# V3s register map
Vendor: Allwinner; Series: V3s; File version: 0.1
CPU: ARM Cortex-A7 MP1 0, little endian, MPU, no FPU, 0 interrupt priority bits
Registers are 32-bit, read-write, reset 0x0 unless marked. A register's access mark holds for its fields unless they carry their own. Offsets are from the block's base; [hi:lo] are bit positions.

## USB_OTG_EHCI0/OHCI0 (part 2 of 2)
Base 0x01C1A000
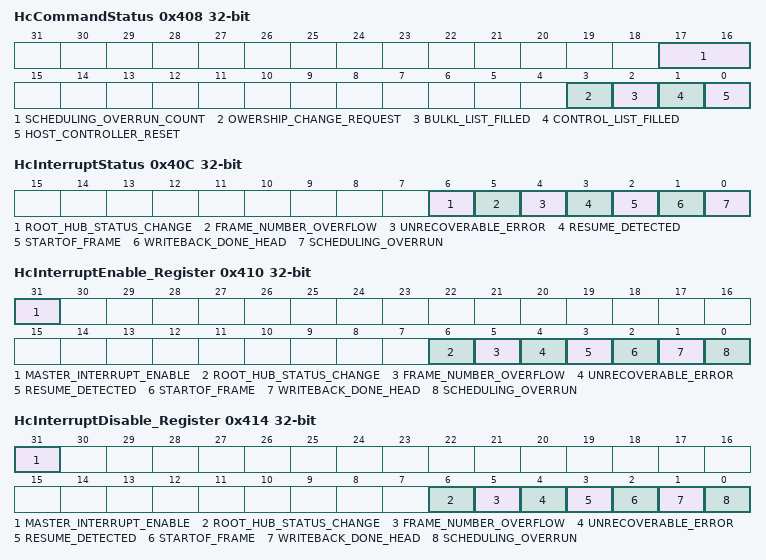
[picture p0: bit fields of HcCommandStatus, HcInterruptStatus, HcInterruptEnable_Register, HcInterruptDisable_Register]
0x408 HcCommandStatus
  [17:16] SCHEDULING_OVERRUN_COUNT ro — SchedulingOverrunCount These bits are incremented on each scheduling overrun error. It is initialized to 00b and wraps around at 11b. This will be incremented when a scheduling overrun is detected even if SchedulingOverrun in HcInterruptStatus has already been set. This is used by HCD to monitor any persistent scheduling problem.
  [3] OWERSHIP_CHANGE_REQUEST — OwershipChangeRequest This bit is set by an OS HCD to request a change of control of the HC. When set HC will set the OwnershipChange field in HcInterruptStatus. After the changeover, this bit is cleared and remains so until the next request from OS HCD.
  [2] BULKL_LIST_FILLED — BulklListFilled This bit is used to indicate whether there are any TDs on the Bulk list. It is set by HCD whenever it adds a TD to an ED in the Bulk list. When HC begins to process the head of the Bulk list, it checks BLF. As long as BulkListFilled is 0, HC will not start processing the Bulk list. If BulkListFilled is 1, HC will start processing the Bulk list and will set BF to 0. If HC finds a TD on the list, then HC will set BulkListFilled to 1 causing the Bulk list processing to continue. If no TD is found on the Bulk list, and if HCD does not set BulkListFilled, then BulkListFilled will still be 0 when HC completes processing the Bulk list and Bulk list processing will stop.
  [1] CONTROL_LIST_FILLED — ControlListFilled This bit is used to indicate whether there are any TDs on the Control list. It is set by HCD whenever it adds a TD to an ED in the Control list. When HC begins to process the head of the Control list, it checks CLF. As long as ControlListFilled is 0, HC will not start processing the Control list. If CF is 1, HC will start processing the Control list and will set ControlListFilled to 0. If HC finds a TD on the list, then HC will set ControlListFilled to 1 causing the Control list processing to continue. If no TD is found on the Control list, and if the HCD does not set ControlListFilled, then ControlListFilled will still be 0 when HC completes processing the Control list and Control list processing will stop.
  [0] HOST_CONTROLLER_RESET — HostControllerReset This bit is by HCD to initiate a software reset of HC. Regardless of the functional state of HC, it moves to the USBSuspend state in which most of the operational registers are reset except those stated otherwise; e.g, the InteruptRouting field of HcControl, and no Host bus accesses are allowed. This bit is cleared by HC upon the completion of the reset operation. The reset operation must be completed within 10 ms. This bit, when set, should not cause a reset to the Root Hub and no subsequent reset signaling should be asserted to its downstream ports.
0x40C HcInterruptStatus
  [6] ROOT_HUB_STATUS_CHANGE — RootHubStatusChange This bit is set when the content of HcRhStatus or the content of any of HcRhPortStatus[NumberofDownstreamPort] has changed.
  [5] FRAME_NUMBER_OVERFLOW — FrameNumberOverflow This bit is set when the MSb of HcFmNumber (bit 15) changes value, from 0 to 1 or from 1 to 0, and after HccaFrameNumber has been updated.
  [4] UNRECOVERABLE_ERROR — UnrecoverableError This bit is set when HC detects a system error not related to USB. HC should not proceed with any processing nor signaling before the system error has been corrected. HCD clears this bit after HC has been reset.
  [3] RESUME_DETECTED — ResumeDetected This bit is set when HC detects that a device on the USB is asserting resume signaling. It is the transition from no resume signaling to resume signaling causing this bit to be set. This bit is not set when HCD sets the USBRseume state.
  [2] STARTOF_FRAME — StartofFrame This bit is set by HC at each start of frame and after the update of HccaFrameNumber. HC also generates a SOF token at the same time.
  [1] WRITEBACK_DONE_HEAD — WritebackDoneHead This bit is set immediately after HC has written HcDoneHead to HccaDoneHead. Further updates of the HccaDoneHead will not occur until this bit has been cleared. HCD should only clear this bit after it has saved the content of HccaDoneHead.
  [0] SCHEDULING_OVERRUN — SchedulingOverrun This bit is set when the USB schedule for the current Frame overruns and after the update of HccaFrameNumber. A scheduling overrun will also cause the SchedulingOverrunCount of HcCommandStatus to be Incremented.
0x410 HcInterruptEnable_Register
  [31] MASTER_INTERRUPT_ENABLE — MasterInterruptEnable A `0` writtern to this field is ignored by HC. A `1` written to this field enables interrupt generation due to events specified in the other bits of this register. This is used by HCD as Master Interrupt Enable.
  [6] ROOT_HUB_STATUS_CHANGE — RootHubStatusChange Interrupt Enable 0 Ignore; 1 Enable interrupt generation due to Root Hub Status Change;
  [5] FRAME_NUMBER_OVERFLOW — FrameNumberOverflow Interrupt Enable 0 Ignore; 1 Enable interrupt generation due to Frame Number Over Flow;
  [4] UNRECOVERABLE_ERROR — UnrecoverableError Interrupt Enable 0 Ignore; 1 Enable interrupt generation due to Unrecoverable Error;
  [3] RESUME_DETECTED — ResumeDetected Interrupt Enable 0 Ignore; 1 Enable interrupt generation due to Resume Detected;
  [2] STARTOF_FRAME — StartofFrame Interrupt Enable 0 Ignore; 1 Enable interrupt generation due to Start of Flame;
  [1] WRITEBACK_DONE_HEAD — WritebackDoneHead Interrupt Enable 0 Ignore; 1 Enable interrupt generation due to Write back Done Head;
  [0] SCHEDULING_OVERRUN — SchedulingOverrun Interrupt Enable 0 Ignore; 1 Enable interrupt generation due to Scheduling Overrun;
0x414 HcInterruptDisable_Register
  [31] MASTER_INTERRUPT_ENABLE — MasterInterruptEnable A written `0` to this field is ignored by HC. A `1` written to this field disables interrupt generation due events specified in the other bits of this register. This field is set after a hardware or software reset.
  [6] ROOT_HUB_STATUS_CHANGE — RootHubStatusChange Interrupt Disable 0 Ignore; 1 Disable interrupt generation due to Root Hub Status Change;
  [5] FRAME_NUMBER_OVERFLOW — FrameNumberOverflow Interrupt Disable 0 Ignore; 1 Disable interrupt generation due to Frame Number Over Flow;
  [4] UNRECOVERABLE_ERROR — UnrecoverableError Interrupt Disable 0 Ignore; 1 Disable interrupt generation due to Unrecoverable Error;
  [3] RESUME_DETECTED — ResumeDetected Interrupt Disable 0 Ignore; 1 Disable interrupt generation due to Resume Detected;
  [2] STARTOF_FRAME — StartofFrame Interrupt Disable 0 Ignore; 1 Disable interrupt generation due to Start of Flame;
  [1] WRITEBACK_DONE_HEAD — WritebackDoneHead Interrupt Disable 0 Ignore; 1 Disable interrupt generation due to Write back Done Head;
  [0] SCHEDULING_OVERRUN — SchedulingOverrun Interrupt Disable 0 Ignore; 1 Disable interrupt generation due to Scheduling Overrun;
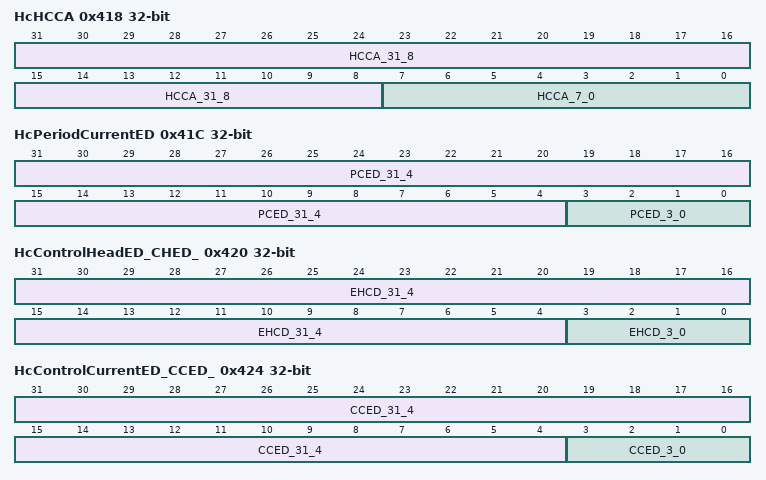
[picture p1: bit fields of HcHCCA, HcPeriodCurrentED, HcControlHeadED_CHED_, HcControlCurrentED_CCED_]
0x418 HcHCCA
  [31:8] HCCA_31_8 — HCCA[31:8] This is the base address of the Host Controller Communication Area. This area is used to hold the control structures and the Interrupt table that are accessed by both the Host Controller and the Host Controller Driver.
  [7:0] HCCA_7_0 ro — HCCA[7:0] The alignment restriction in HcHCCA register is evaluated by examining the number of zeros in the lower order bits. The minimum alignment is 256 bytes, therefore, bits 0 through 7 must always return 0 when read.
0x41C HcPeriodCurrentED
  [31:4] PCED_31_4 ro — PCED[31:4] This is used by HC to point to the head of one of the Periodec list which will be processed in the current Frame. The content of this register is updated by HC after a periodic ED has been processed. HCD may read the content in determining which ED is currently being processed at the time of reading.
  [3:0] PCED_3_0 ro — PCED[3:0] Because the general TD length is 16 bytes, the memory structure for the TD must be aligned to a 16-byte boundary. So the lower bits in the PCED, through bit 0 to bit 3 must be zero in this field.
0x420 HcControlHeadED_CHED_
  [31:4] EHCD_31_4 — EHCD[31:4] The HcControlHeadED register contains the physical address of the first Endpoint Descriptor of the Control list. HC traverse the Control list starting with the HcControlHeadED pointer. The content is loaded from HCCA during the initialization of HC.
  [3:0] EHCD_3_0 ro — EHCD[3:0] Because the general TD length is 16 bytes, the memory structure for the TD must be aligned to a 16-byte boundary. So the lower bits in the PCED, through bit 0 to bit 3 must be zero in this field.
0x424 HcControlCurrentED_CCED_
  [31:4] CCED_31_4 — CCED[31:4] The pointer is advanced to the next ED after serving the present one. HC will continue processing the list from where it left off in the last Frame. When it reaches the end of the Control list, HC checks the ControlListFilled of in HcCommandStatus. If set, it copies the content of HcControlHeadED to HcControlCurrentED and clears the bit. If not set, it does nothing. HCD is allowed to modify this register only when the ControlListEnable of HcControl is cleared. When set, HCD only reads the instantaneous value of this register. Initially, this is set to zero to indicate the end of the Control list.
  [3:0] CCED_3_0 ro — CCED[3:0] Because the general TD length is 16 bytes, the memory structure for the TD must be aligned to a 16-byte boundary. So the lower bits in the PCED, through bit 0 to bit 3 must be zero in this field.
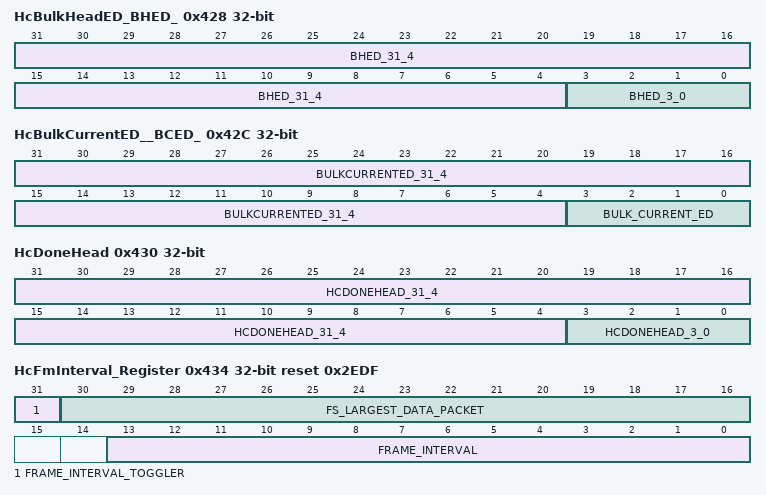
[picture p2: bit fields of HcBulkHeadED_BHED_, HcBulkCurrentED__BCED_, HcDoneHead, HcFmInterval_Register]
0x428 HcBulkHeadED_BHED_
  [31:4] BHED_31_4 — BHED[31:4] The HcBulkHeadED register contains the physical address of the first Endpoint Descriptor of the Bulk list. HC traverses the Bulk list starting with the HcBulkHeadED pointer. The content is loaded from HCCA during the initialization of HC.
  [3:0] BHED_3_0 ro — BHED[3:0] Because the general TD length is 16 bytes, the memory structure for the TD must be aligned to a 16-byte boundary. So the lower bits in the PCED, through bit 0 to bit 3 must be zero in this field.
0x42C HcBulkCurrentED__BCED_
  [31:4] BULKCURRENTED_31_4 — BulkCurrentED[31:4] This is advanced to the next ED after the HC has served the present one. HC continues processing the list from where it left off in the last Frame. When it reaches the end of the Bulk list, HC checks the ControlListFilled of HcControl. If set, it copies the content of HcBulkHeadED to HcBulkCurrentED and clears the bit. If it is not set, it does nothing. HCD is only allowed to modify this register when the BulkListEnable of HcControl is cleared. When set, the HCD only reads the instantaneous value of this register. This is initially set to zero to indicate the end of the Bulk list.
  [3:0] BULK_CURRENT_ED ro — BulkCurrentED [3:0] Because the general TD length is 16 bytes, the memory structure for the TD must be aligned to a 16-byte boundary. So the lower bits in the PCED, through bit 0 to bit 3 must be zero in this field.
0x430 HcDoneHead
  [31:4] HCDONEHEAD_31_4 ro — HcDoneHead[31:4] When a TD is completed, HC writes the content of HcDoneHead to the NextTD field of the TD. HC then overwrites the content of HcDoneHead with the address of this TD. This is set to zero whenever HC writes the content of this register to HCCA. It also sets the WritebackDoneHead of HcInterruptStatus.
  [3:0] HCDONEHEAD_3_0 ro — HcDoneHead[3:0] Because the general TD length is 16 bytes, the memory structure for the TD must be aligned to a 16-byte boundary. So the lower bits in the PCED, through bit 0 to bit 3 must be zero in this field.
0x434 HcFmInterval_Register reset 0x2EDF
  [31] FRAME_INTERVAL_TOGGLER — FrameIntervalToggler HCD toggles this bit whenever it loads a new value to FrameInterval.
  [30:16] FS_LARGEST_DATA_PACKET — FSLargestDataPacket This field specifies a value which is loaded into the Largest Data Packet Counter at the beginning of each frame. The counter value represents the largest amount of data in bits which can be sent or received by the HC in a single transaction at any given time without causing scheduling overrun. The field value is calculated by the HCD.
  [13:0] FRAME_INTERVAL — FrameInterval This specifies the interval between two consecutive SOFs in bit times. The nominal value is set to be 11,999. HCD should store the current value of this field before resetting HC. By setting the HostControllerReset field of HcCommandStatus as this will cause the HC to reset this field to its nominal value. HCD may choose to restore the stored value upon the completion of the Reset sequence.
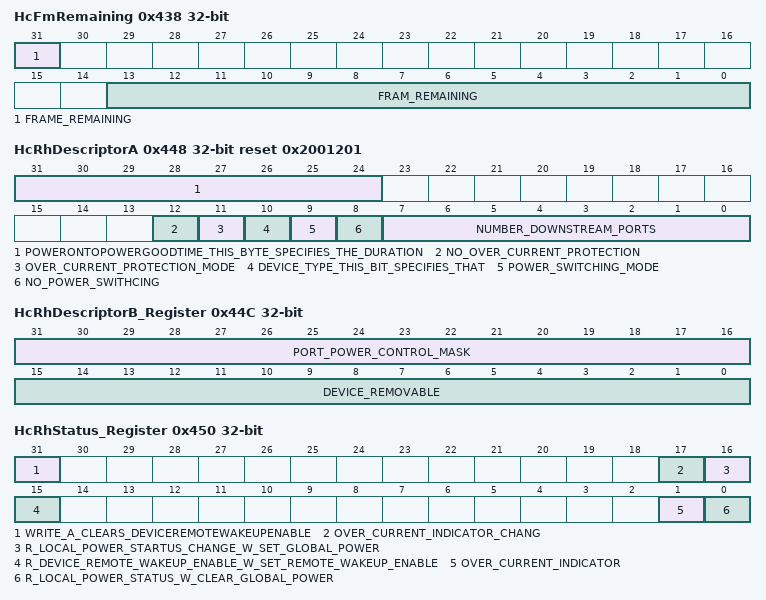
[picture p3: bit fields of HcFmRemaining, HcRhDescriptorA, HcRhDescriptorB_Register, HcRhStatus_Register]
0x438 HcFmRemaining
  [31] FRAME_REMAINING ro — FrameRemaining Toggle This bit is loaded from the FrameIntervalToggle field of HcFmInterval whenever FrameRemaining reaches 0. This bit is used by HCD for the synchronization between FrameInterval and FrameRemaining.
  [13:0] FRAM_REMAINING ro — FramRemaining This counter is decremented at each bit time. When it reaches zero, it is reset by loading the FrameInterval value specified in HcFmInterval at the next bit time boundary. When entering the USBOPERATIONAL state, HC re-loads the content with the FrameInterval of HcFmInterval and uses the updated value from the next SOF.
0x43C HcFmNumber
  [15:0] FRAME_NUMBER ro — FrameNumber This is incremented when HcFmRemaining is re-loaded. It will be rolled over to 0x0 after 0x0ffff. When entering the USBOPERATIONAL state, this will be incremented automatically. The content will be written to HCCA after HC has incremented the FrameNumber at each frame boundary and sent a SOF but before HC reads the first ED in that Frame. After writing to HCCA, HC will set the StartofFrame in HcInterruptStatus.
0x440 HcPeriodicStatus
  [13:0] PERIODIC_START — PeriodicStart After a hardware reset, this field is cleared. This is then set by HCD during the HC initialization. The value is calculated roughly as 10% off from HcFmInterval. A typical value will be 0x2A3F (0x3e67??). When HcFmRemaining reaches the value specified, processing of the periodic lists will have priority over Control/Bulk processing. HC will therefore start processing the Interrupt list after completing the current Control or Bulk transaction that is in progress.
0x444 HcLSThreshold reset 0x628
  [11:0] LS_THRESHOLD — LSThreshold This field contains a value which is compared to the FrameRemaining field prior to initiating a Low Speed transaction. The transaction is started only if FrameRemaining this field. The value is calculated by HCD with the consideration of transmission and setup overhead.
0x448 HcRhDescriptorA reset 0x2001201
  [31:24] POWERONTOPOWERGOODTIME_THIS_BYTE_SPECIFIES_THE_DURATION — PowerOnToPowerGoodTime[POTPGT] This byte specifies the duration HCD has to wait before accessing a powered-on port of the Root Hub. It is implementation-specific. The unit of time is 2 ms. The duration is calculated as POTPGT * 2ms.
  [12] NO_OVER_CURRENT_PROTECTION — NoOverCurrentProtection This bit describes how the overcurrent status for the Root Hub ports are reported. When this bit is cleared, the OverCurrentProtectionMode field specifies global or per-port reporting. 0 Over-current status is reported collectively for all downstream ports. 1 No overcurrent protection supported.
  [11] OVER_CURRENT_PROTECTION_MODE — OverCurrentProtectionMode This bit describes how the overcurrent status for the Root Hub ports are reported. At reset, these fields should reflect the same mode as PowerSwitchingMode. This field is valid only if the NoOverCurrentProtection field is cleared. 0 Over-current status is reported collectively for all downstream ports. 1 Over-current status is reported on per-port basis.
  [10] DEVICE_TYPE_THIS_BIT_SPECIFIES_THAT ro — Device Type This bit specifies that the Root Hub is not a compound device. The Root Hub is not permitted to be a compound device. This field should always read/write 0.
  [9] POWER_SWITCHING_MODE — PowerSwitchingMode This bit is used to specify how the power switching of the Root Hub ports is controlled. It is implementation-specific. This field is only valid if the NoPowerSwitching field is cleared. 0 All ports are powered at the same time. 1 Each port is powered individually. This mode allows port power to be controlled by either the global switch or per-port switching. If the PortPowerControlMask bit is set, the port responds only to port power commands (Set/ClearPortPower). If the port mask is cleared, then the port is controlled only by the global power switch (Set/ClearGlobalPower).
  [8] NO_POWER_SWITHCING — NoPowerSwithcing These bits are used to specify whether power switching is supported or ports are always powered. It is implementation-specific. When this bit is cleared, the PowerSwitchingMode specifies global or per-port switching. 0 Ports are power switched. 1 Ports are always powered on when the HC is powered on.
  [7:0] NUMBER_DOWNSTREAM_PORTS ro — NumberDownstreamPorts These bits specify the number of downstream ports supported by the Root Hub. It is implementation-specific. The minimum number of ports is 1. The maximum number of ports supported.
0x44C HcRhDescriptorB_Register
  [31:16] PORT_POWER_CONTROL_MASK — PortPowerControlMask Each bit indicates if a port is affected by a global power control command when PowerSwitchingMode is set. When set, the port's power state is only affected by per-port power control (Set/ClearPortPower). When cleared, the port is controlled by the global power switch (Set/ClearGlobalPower). If the device is configured to global switching mode (PowerSwitchingMode = 0 ), this field is not valid. Bit0 Reserved Bit1 Ganged-power mask on Port #1. Bit2 Ganged-power mask on Port #2. ... Bit15 Ganged-power mask on Port #15.
  [15:0] DEVICE_REMOVABLE — DeviceRemovable Each bit is dedicated to a port of the Root Hub. When cleared, the attached device is removable. When set, the attached device is not removable. Bit0 Reserved Bit1 Device attached to Port #1. Bit2 Device attached to Port #2. ... Bit15 Device attached to Port #15.
0x450 HcRhStatus_Register
  [31] WRITE_A_CLEARS_DEVICEREMOTEWAKEUPENABLE wo — (write)ClearRemoteWakeupEnable Write a `1` clears DeviceRemoteWakeupEnable. Write a `0` has no effect.
  [17] OVER_CURRENT_INDICATOR_CHANG — OverCurrentIndicatorChang This bit is set by hardware when a change has occurred to the OverCurrentIndicator field of this register. The HCD clears this bit by writing a `1`.Writing a `0` has no effect.
  [16] R_LOCAL_POWER_STARTUS_CHANGE_W_SET_GLOBAL_POWER — (read)LocalPowerStartusChange The Root Hub does not support the local power status features, thus, this bit is always read as `0`. (write)SetGlobalPower In global power mode (PowerSwitchingMode=0), This bit is written to `1` to turn on power to all ports (clear PortPowerStatus). In per-port power mode, it sets PortPowerStatus only on ports whose PortPowerControlMask bit is not set. Writing a `0` has no effect.
  [15] R_DEVICE_REMOTE_WAKEUP_ENABLE_W_SET_REMOTE_WAKEUP_ENABLE — (read)DeviceRemoteWakeupEnable This bit enables a ConnectStatusChange bit as a resume event, causing a USBSUSPEND to USBRESUME state transition and setting the ResumeDetected interrupt. 0 ConnectStatusChange is not a remote wakeup event. 1 ConnectStatusChange is a remote wakeup event. (write)SetRemoteWakeupEnable Writing a `1` sets DeviceRemoveWakeupEnable. Writing a `0` has no effect.
  [1] OVER_CURRENT_INDICATOR ro — OverCurrentIndicator This bit reports overcurrent conditions when the global reporting is implemented. When set, an overcurrent condition exists. When cleared, all power operations are normal. If per-port overcurrent protection is implemented this bit is always `0`
  [0] R_LOCAL_POWER_STATUS_W_CLEAR_GLOBAL_POWER — (Read)LocalPowerStatus When read, this bit returns the LocalPowerStatus of the Root Hub. The Root Hub does not support the local power status feature; thus, this bit is always read as `0`. (Write)ClearGlobalPower When write, this bit is operated as the ClearGlobalPower. In global power mode (PowerSwitchingMode=0), This bit is written to `1` to turn off power to all ports (clear PortPowerStatus). In per-port power mode, it clears PortPowerStatus only on ports whose PortPowerControlMask bit is not set. Writing a `0` has no effect.
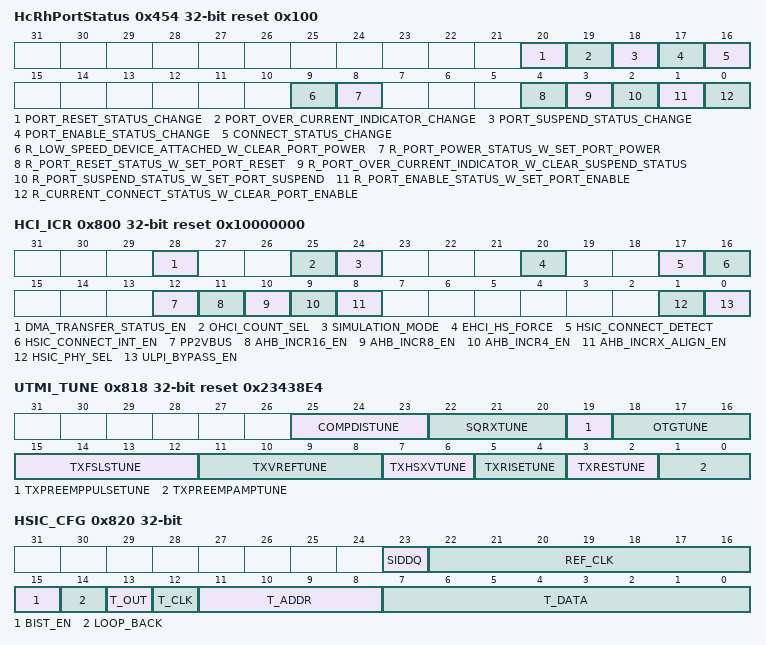
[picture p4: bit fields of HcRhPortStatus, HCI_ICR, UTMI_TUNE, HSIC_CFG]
0x454 HcRhPortStatus reset 0x100 (reset mask 0x1F011F)
  [20] PORT_RESET_STATUS_CHANGE — PortResetStatusChange This bit is set at the end of the 10-ms port reset signal. The HCD writes a `1` to clear this bit. Writing a `0` has no effect. 0 port reset is not complete 1 port reset is complete
  [19] PORT_OVER_CURRENT_INDICATOR_CHANGE — PortOverCurrentIndicatorChange This bit is valid only if overcurrent conditions are reported on a per-port basis. This bit is set when Root Hub changes the PortOverCurrentIndicator bit. The HCD writes a `1` to clear this bit. Writing a `0` has no effect. 0 no change in PortOverCurrentIndicator 1 PortOverCurrentIndicator has changed
  [18] PORT_SUSPEND_STATUS_CHANGE — PortSuspendStatusChange This bit is set when the full resume sequence has been completed. This sequence includes the 20-s resume pulse, LS EOP, and 3-ms resychronization delay. The HCD writes a `1` to clear this bit. Writing a `0` has no effect. This bit is also cleared when ResetStatusChange is set. 0 resume is not completed 1 resume completed
  [17] PORT_ENABLE_STATUS_CHANGE — PortEnableStatusChange This bit is set when hardware events cause the PortEnableStatus bit to be cleared. Changes from HCD writes do not set this bit. The HCD writes a `1` to clear this bit. Writing a `0` has no effect. 0 no change in PortEnableStatus 1 change in PortEnableStatus
  [16] CONNECT_STATUS_CHANGE — ConnectStatusChange This bit is set whenever a connect or disconnect event occurs. The HCD writes a `1` to clear this bit. Writing a `0` has no effect. If CurrentConnectStatus is cleared when a SetPortReset,SetPortEnable, or SetPortSuspend write occurs, this bit is set to force the driver to re-evaluate the connection status since these writes should not occur if the port is disconnected. 0 no change in PortEnableStatus 1 change in PortEnableStatus Note: If the DeviceRemovable[NDP] bit is set, this bit is set only after a Root Hub reset to inform the system that the device is attached.
  [9] R_LOW_SPEED_DEVICE_ATTACHED_W_CLEAR_PORT_POWER — (read)LowSpeedDeviceAttached This bit indicates the speed of the device attached to this port. When set, a Low Speed device is attached to this port. When clear, a Full Speed device is attached to this port. This field is valid only when the CurrentConnectStatus is set. 0 full speed device attached 1 low speed device attached (write)ClearPortPower The HCD clears the PortPowerStatus bit by writing a `1` to this bit. Writing a `0` has no effect.
  [8] R_PORT_POWER_STATUS_W_SET_PORT_POWER — (read)PortPowerStatus This bit reflects the port`s power status, regardless of the type of power switching implemented. This bit is cleared if an overcurrent condition is detected. HCD sets this bit by writing SetPortPower or SetGlobalPower. HCD clears this bit by writing ClearPortPower or ClearGlobalPower. Which power control switches are enabled is determined by PowerSwitchingMode and PortPortControlMask[NumberDownstreamPort]. In global switching mode(PowerSwitchingMode=0), only Set/ClearGlobalPower controls this bit. In per-port power switching (PowerSwitchingMode=1), if the PortPowerControlMask[NDP] bit for the port is set, only Set/ClearPortPower commands are enabled. If the mask is not set, only Set/ClearGlobalPower commands are enabled. When port power is disabled, CurrentConnectStatus, PortEnableStatus, PortSuspendStatus, and PortResetStatus should be reset. 0 port power is off 1 port power is on (write)SetPortPower The HCD writes a `1` to set the PortPowerStatus bit. Writing a `0` has no effect. Note: This bit is always reads `1b` if power switching is not supported.
  [4] R_PORT_RESET_STATUS_W_SET_PORT_RESET — (read)PortResetStatus When this bit is set by a write to SetPortReset, port reset signaling is asserted. When reset is completed, this bit is cleared when PortResetStatusChange is set. This bit cannot be set if CurrentConnectStatus is cleared. 0 port reset signal is not active 1 port reset signal is active (write)SetPortReset The HCD sets the port reset signaling by writing a `1` to this bit. Writing a `0` has no effect. If CurrentConnectStatus is cleared, this write does not set PortResetStatus, but instead sets ConnectStatusChange. This informs the driver that it attempted to reset a disconnected port.
  [3] R_PORT_OVER_CURRENT_INDICATOR_W_CLEAR_SUSPEND_STATUS — (read)PortOverCurrentIndicator This bit is only valid when the Root Hub is configured in such a way that overcurrent conditions are reported on a per-port basis. If per-port overcurrent reporting is not supported, this bit is set to 0. If cleared, all power operations are normal for this port. If set, an overcurrent condition exists on this port. This bit always reflects the overcurrent input signal. 0 no overcurrent condition. 1 overcurrent condition detected. (write)ClearSuspendStatus The HCD writes a `1` to initiate a resume. Writing a `0` has no effect. A resume is initiated only if PortSuspendStatus is set.
  [2] R_PORT_SUSPEND_STATUS_W_SET_PORT_SUSPEND — (read)PortSuspendStatus This bit indicates the port is suspended or in the resume sequence. It is set by a SetSuspendState write and cleared when PortSuspendStatusChange is set at the end of the resume interval. This bit cannot be set if CurrentConnectStatus is cleared. This bit is also cleared when PortResetStatusChange is set at the end of the port reset or when the HC is placed in the USBRESUME state. If an upstream resume is in progress, it should propagate to the HC. 0 port is not suspended 1 port is suspended (write)SetPortSuspend The HCD sets the PortSuspendStatus bit by writing a `1` to this bit. Writing a `0` has no effect. If CurrentConnectStatus is cleared, this write does not set PortSuspendStatus; instead it sets ConnectStatusChange. This informs the driver that it attempted to suspend a disconnected port.
  [1] R_PORT_ENABLE_STATUS_W_SET_PORT_ENABLE — (read)PortEnableStatus This bit indicates whether the port is enabled or disabled. The Root Hub may clear this bit when an overcurrent condition, disconnect event, switched-off power, or operational bus error such as babble is detected. This change also causes PortEnabledStatusChange to be set. HCD sets this bit by writing SetPortEnable and clears it by writing ClearPortEnable. This bit cannot be set when CurrentConnectStatus is cleared. This bit is also set, if not already, at the completion of a port reset when ResetStatusChange is set or port suspend when SuspendStatusChange is set. 0 port is disabled 1 port is enabled (write)SetPortEnable The HCD sets PortEnableStatus by writing a `1`. Writing a `0` has no effect. If CurrentConnectStatus is cleared, this write does not set PortEnableStatus, but instead sets ConnectStatusChange. This informs the driver that it attempted to enable a disconnected Port.
  [0] R_CURRENT_CONNECT_STATUS_W_CLEAR_PORT_ENABLE — (read)CurrentConnectStatus This bit reflects the current state of the downstream port. 0 No device connected 1 Device connected (write)ClearPortEnable The HCD writes a `1` to clear the PortEnableStatus bit. Writing `0` has no effect. The CurrentConnectStatus is not affected by any write. Note: This bit is always read `1` when the attached device is nonremovalble(DviceRemoveable[NumberDownstreamPort]).
0x800 HCI_ICR reset 0x10000000
  [28] DMA_TRANSFER_STATUS_EN ro — Transfer Status Enable 0: Disable 1: Enable
    0=Disable; 1=Enable
  [25] OHCI_COUNT_SEL — count select 1: Simulation mode, the counters will be much shorter then real time 0: Normal mode, the counters will count full time
    1=Simulation mode, the counters will be much shorter then real time; 0=Normal mode, the counters will count full time
  [24] SIMULATION_MODE — Simulation mode 1: Set PHY in a non-driving mode so the EHCI can detect device connection, this is used only for simulation 0: No effect
    1=Set (Set PHY in a non-driving mode so the EHCI can detect device connection, this is used only for simulation); 0=No_effect
  [20] EHCI_HS_FORCE — HS force Set 1 to this field force the ehci enter the high speed mode during bus reset. This field only valid when the bit 1 is set.
  [17] HSIC_CONNECT_DETECT — Connect detect 1 in this field enable the hsic phy to detect device connect pulse on the bus.
  [16] HSIC_CONNECT_INT_EN — Connect Interrupt Enable Enable the HSIC connect interrupt.
  [12] PP2VBUS — 1: ULPI wrapper interface will automatically set or clear DrvVbus register in ULPI PHY according to the port power status form the root hub 0: ULPI wrapper will ignore the difference between power status of root hub and ULPI PHY
    1=ULPI wrapper interface will automatically set or clear DrvVbus register in ULPI PHY according to the port power status form the root hub; 0=ULPI wrapper will ignore the difference between power status of root hub and ULPI PHY
  [11] AHB_INCR16_EN — Master interface INCR16 enable 1: Use INCR16 when appropriate 0: do not use INCR16,use other enabled INCRX or unspecified length burst INCR
    1=Use INCR16 when appropriate; 0=do_not_use_INCR16_comma_use (do not use INCR16,use other enabled INCRX or unspecified length burst INCR)
  [10] AHB_INCR8_EN — Master interface INCR8 enable 1: Use INCR8 when appropriate 0: do not use INCR8,use other enabled INCRX or unspecified length burst INCR
    1=Use INCR8 when appropriate; 0=do_not_use_INCR8_comma_use (do not use INCR8,use other enabled INCRX or unspecified length burst INCR)
  [9] AHB_INCR4_EN — Master interface burst type INCR4 enable 1: Use INCR4 when appropriate 0: do not use INCR4,use other enabled INCRX or unspecified length burst INCR
    1=Use INCR4 when appropriate; 0=do_not_use_INCR4_comma_use (do not use INCR4,use other enabled INCRX or unspecified length burst INCR)
  [8] AHB_INCRX_ALIGN_EN — Master interface INCRX align enable 1: start INCRx burst only on burst x-align address 0: Start burst on any double word boundary Note: This bit must enable if any bit of 11:9 is enabled
    1=start INCRx burst only on burst x-align address; 0=Start burst on any double word boundary Note: This bit must enable if any bit of 11:9 is enabled
  [1] HSIC_PHY_SEL — Phy Select 0:Select the UTMI Phy for the EHCI 1:Select the HSIC Phy for the EHCI
  [0] ULPI_BYPASS_EN — bypass enable 1: Enable UTMI interface, disable ULPI interface 0: Enable ULPI interface, disable UTMI interface
    1=Enable UTMI interface, disable ULPI interface; 0=Enable ULPI interface, disable UTMI interface
0x804 HSIC_STATUS
  [16] HSIC — Connect Status 1 in this field indicates a device connect pulse being detected on the bus. This field only valid when the EHCI HS force bit and the HSIC Phy Select bit is set. When the HSIC Connect Interrupt Enable is set, 1 in this bit will generate an interrupt to the system. This register is valid on HCI1.
0x818 UTMI_TUNE reset 0x23438E4
  [25:23] COMPDISTUNE, [22:20] SQRXTUNE, [19] TXPREEMPPULSETUNE, [18:16] OTGTUNE, [15:12] TXFSLSTUNE, [11:8] TXVREFTUNE, [7:6] TXHSXVTUNE, [5:4] TXRISETUNE, [3:2] TXRESTUNE, [1:0] TXPREEMPAMPTUNE
0x820 HSIC_CFG
  [23] SIDDQ
  [22:16] REF_CLK
  [15] BIST_EN
  [14] LOOP_BACK
  [13] T_OUT — T OUT SEL
  [12] T_CLK
  [11:8] T_ADDR
  [7:0] T_DATA
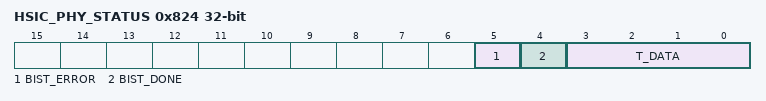
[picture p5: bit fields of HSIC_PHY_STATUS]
0x824 HSIC_PHY_STATUS
  [5] BIST_ERROR — BIST Error 0: HSIC BIST Pass 1: HSIC BIST Fail
    0=HSIC_BIST_Pass; 1=HSIC_BIST_Fail
  [4] BIST_DONE — Bist Done 0: HSIC BIST is in progress 1: HSIC BIST is done
    0=in (HSIC BIST is in progress); 1=done (HSIC BIST is done)
  [3:0] T_DATA — T DATA OUT HSIC Test Data Out
